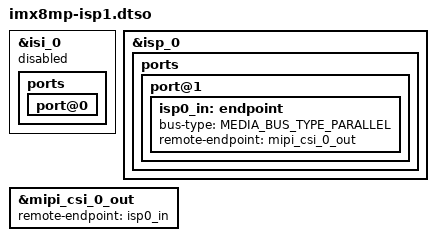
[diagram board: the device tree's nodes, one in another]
// SPDX-License-Identifier: (GPL-2.0+ OR MIT)
/*
 * Copyright 2022 Ideas on Board Oy
 */

/dts-v1/;
/plugin/;

#include <dt-bindings/media/video-interfaces.h>

&isi_0 {
	status = "disabled";

	ports {
		port@0 {
			/delete-node/ endpoint;
		};
	};
};

&isp_0 {
	status = "okay";

	ports {
		port@1 {
			isp0_in: endpoint {
				bus-type = <MEDIA_BUS_TYPE_PARALLEL>;
				remote-endpoint = <&mipi_csi_0_out>;
			};
		};
	};
};

&mipi_csi_0_out {
	remote-endpoint = <&isp0_in>;
};
